AUTOSAR XML (schema 00045)
package /COM/VECTOR/CFG/WORKFLOW/SYSDESC/SYNC
  system SYSTEM: category=ECU_EXTRACT
    system mapping MAPPINGS
      data-mappings:
        data-element=COMPOSITIONTYPE.If_HIL_Vx.Vx, system-signal=Vx
        data-element=COMPOSITIONTYPE.If_HIL_Vx.Cnt, system-signal=Cnt
        data-element=COMPOSITIONTYPE.If_HIL_Cmd.Heartbeat, system-signal=Heartbeat
        data-element=COMPOSITIONTYPE.If_HIL_Cmd.Throttle, system-signal=Throttle
        data-element=COMPOSITIONTYPE.If_HIL_Cmd.Pcon, system-signal=Pcon
        data-element=COMPOSITIONTYPE.If_HIL_Cmd.Fault, system-signal=Fault
    root-software-compositions:
      root sw composition prototype COMPOSITIONTYPE: flat-map=FLATMAP, software-composition=COMPOSITIONTYPE
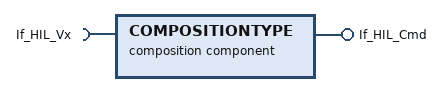
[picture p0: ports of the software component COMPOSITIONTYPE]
  composition sw component type COMPOSITIONTYPE  # UB:Derived from original system description
    require port If_HIL_Vx: required-interface=If_HIL_Vx
    provide port If_HIL_Cmd: provided-interface=If_HIL_Cmd
    6 x component:
      BswM: type=BswM
      Det: type=Det
      EcuM: type=EcuM
      Os_OsCore0_swc: type=Os_OsCore0_swc
      HIL_Controller: type=HIL_Controller
      ComM: type=ComM
    delegate HIL_Controller.R_HIL_Vx <-> outer port If_HIL_Vx  # UB:Derived from original system description
    delegate HIL_Controller.P_HIL_Cmd <-> outer port If_HIL_Cmd  # UB:Derived from original system description
  end to end protection set E2EPROTECTIONSET
  port interface mapping set PORTINTERFACEMAPPINGSET
